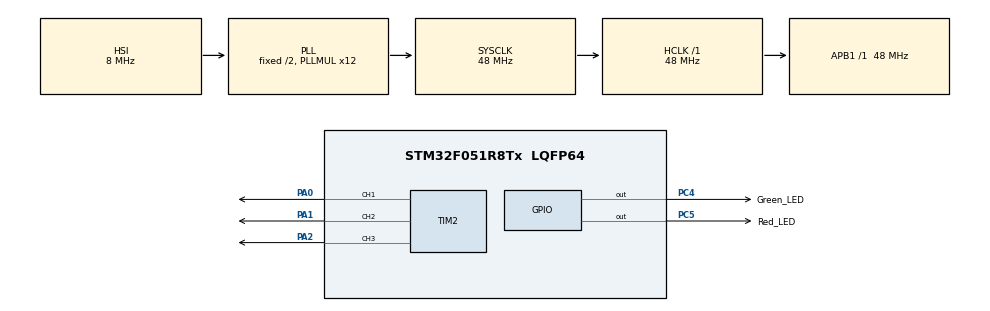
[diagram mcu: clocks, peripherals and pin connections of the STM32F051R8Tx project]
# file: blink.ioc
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Mcu.Family=STM32F0
Mcu.Name=STM32F051R8Tx
Mcu.Package=LQFP64
PA0.Signal=S_TIM2_CH1_ETR
PA1.Signal=S_TIM2_CH2
PA2.Signal=S_TIM2_CH3
PC4.GPIO_Label=Green_LED
PC4.Signal=GPIO_Output
PC5.GPIO_Label=Red_LED
PC5.Signal=GPIO_Output
ProjectManager.HeapSize=0x200
ProjectManager.StackSize=0x400
ProjectManager.TargetToolchain=STM32CubeIDE
RCC.AHBFreq_Value=48000000
RCC.APB1Freq_Value=48000000
RCC.APB1TimFreq_Value=48000000
RCC.HCLKFreq_Value=48000000
RCC.PLLMUL=RCC_PLL_MUL12
RCC.SYSCLKFreq_VALUE=48000000
RCC.SYSCLKSource=RCC_SYSCLKSOURCE_PLLCLK
SH.S_TIM2_CH1_ETR.0=TIM2_CH1,PWM Generation1 CH1
SH.S_TIM2_CH2.0=TIM2_CH2,PWM Generation2 CH2
SH.S_TIM2_CH3.0=TIM2_CH3,PWM Generation3 CH3
TIM2.Channel-PWM\ Generation1\ CH1=TIM_CHANNEL_1
TIM2.Channel-PWM\ Generation2\ CH2=TIM_CHANNEL_2
TIM2.Channel-PWM\ Generation3\ CH3=TIM_CHANNEL_3
VP_TIM2_VS_ClockSourceINT.Mode=Internal
VP_TIM3_VS_ClockSourceINT.Mode=Internal
board=STM32F0DISCOVERY

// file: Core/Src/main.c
/* USER CODE BEGIN Header */
/**
  ******************************************************************************
  * @file           : main.c
  * @brief          : Main program body
  ******************************************************************************
  * @attention
  *
  * <h2><center>&copy; Copyright (c) 2020 STMicroelectronics.
  * All rights reserved.</center></h2>
  *
  * This software component is licensed by ST under BSD 3-Clause license,
  * the "License"; You may not use this file except in compliance with the
  * License. You may obtain a copy of the License at:
  *                        opensource.org/licenses/BSD-3-Clause
  *
  ******************************************************************************
  */
/* USER CODE END Header */
#include "main.h"

TIM_HandleTypeDef htim2;
TIM_HandleTypeDef htim3;

void SystemClock_Config(void);
static void MX_GPIO_Init(void);
static void MX_TIM2_Init(void);
static void MX_TIM3_Init(void);

int main(void)
{

  /* MCU Configuration--------------------------------------------------------*/

  /* Reset of all peripherals, Initializes the Flash interface and the Systick. */
  HAL_Init();

  /* Configure the system clock */
  SystemClock_Config();

  /* Initialize all configured peripherals */
  MX_GPIO_Init();
  MX_TIM2_Init();
  MX_TIM3_Init();
  /* USER CODE BEGIN 2 */
  HAL_GPIO_WritePin(GPIOC, Green_LED_Pin, 1);  // enables the green light as a status light
  /* USER CODE END 2 */

  /* Infinite loop */
  while (1)
  {

  }
}

void SystemClock_Config(void)
{
  RCC_OscInitTypeDef RCC_OscInitStruct = {0};
  RCC_ClkInitTypeDef RCC_ClkInitStruct = {0};

  /** Initializes the RCC Oscillators according to the specified parameters
  * in the RCC_OscInitTypeDef structure.
  */
  RCC_OscInitStruct.OscillatorType = RCC_OSCILLATORTYPE_HSI;
  RCC_OscInitStruct.HSIState = RCC_HSI_ON;
  RCC_OscInitStruct.HSICalibrationValue = RCC_HSICALIBRATION_DEFAULT;
  RCC_OscInitStruct.PLL.PLLState = RCC_PLL_ON;
  RCC_OscInitStruct.PLL.PLLSource = RCC_PLLSOURCE_HSI;
  RCC_OscInitStruct.PLL.PLLMUL = RCC_PLL_MUL12;
  RCC_OscInitStruct.PLL.PREDIV = RCC_PREDIV_DIV1;
  if (HAL_RCC_OscConfig(&RCC_OscInitStruct) != HAL_OK)
  {
    Error_Handler();
  }
  /** Initializes the CPU, AHB and APB buses clocks
  */
  RCC_ClkInitStruct.ClockType = RCC_CLOCKTYPE_HCLK|RCC_CLOCKTYPE_SYSCLK
                              |RCC_CLOCKTYPE_PCLK1;
  RCC_ClkInitStruct.SYSCLKSource = RCC_SYSCLKSOURCE_PLLCLK;
  RCC_ClkInitStruct.AHBCLKDivider = RCC_SYSCLK_DIV1;
  RCC_ClkInitStruct.APB1CLKDivider = RCC_HCLK_DIV1;

  if (HAL_RCC_ClockConfig(&RCC_ClkInitStruct, FLASH_LATENCY_1) != HAL_OK)
  {
    Error_Handler();
  }
}

static void MX_TIM2_Init(void)
{

  TIM_ClockConfigTypeDef sClockSourceConfig = {0};
  TIM_MasterConfigTypeDef sMasterConfig = {0};
  TIM_OC_InitTypeDef sConfigOC = {0};

  htim2.Instance = TIM2;
  htim2.Init.Prescaler = 0;
  htim2.Init.CounterMode = TIM_COUNTERMODE_UP;
  htim2.Init.Period = 4294967295;
  htim2.Init.ClockDivision = TIM_CLOCKDIVISION_DIV1;
  htim2.Init.AutoReloadPreload = TIM_AUTORELOAD_PRELOAD_DISABLE;
  if (HAL_TIM_Base_Init(&htim2) != HAL_OK)
  {
    Error_Handler();
  }
  sClockSourceConfig.ClockSource = TIM_CLOCKSOURCE_INTERNAL;
  if (HAL_TIM_ConfigClockSource(&htim2, &sClockSourceConfig) != HAL_OK)
  {
    Error_Handler();
  }
  if (HAL_TIM_PWM_Init(&htim2) != HAL_OK)
  {
    Error_Handler();
  }
  sMasterConfig.MasterOutputTrigger = TIM_TRGO_RESET;
  sMasterConfig.MasterSlaveMode = TIM_MASTERSLAVEMODE_DISABLE;
  if (HAL_TIMEx_MasterConfigSynchronization(&htim2, &sMasterConfig) != HAL_OK)
  {
    Error_Handler();
  }
  sConfigOC.OCMode = TIM_OCMODE_PWM1;
  sConfigOC.Pulse = 0;
  sConfigOC.OCPolarity = TIM_OCPOLARITY_HIGH;
  sConfigOC.OCFastMode = TIM_OCFAST_DISABLE;
  if (HAL_TIM_PWM_ConfigChannel(&htim2, &sConfigOC, TIM_CHANNEL_1) != HAL_OK)
  {
    Error_Handler();
  }
  if (HAL_TIM_PWM_ConfigChannel(&htim2, &sConfigOC, TIM_CHANNEL_2) != HAL_OK)
  {
    Error_Handler();
  }
  if (HAL_TIM_PWM_ConfigChannel(&htim2, &sConfigOC, TIM_CHANNEL_3) != HAL_OK)
  {
    Error_Handler();
  }
  HAL_TIM_MspPostInit(&htim2);

}

static void MX_TIM3_Init(void)
{

  TIM_ClockConfigTypeDef sClockSourceConfig = {0};
  TIM_MasterConfigTypeDef sMasterConfig = {0};

  htim3.Instance = TIM3;
  htim3.Init.Prescaler = 0;
  htim3.Init.CounterMode = TIM_COUNTERMODE_UP;
  htim3.Init.Period = 65535;
  htim3.Init.ClockDivision = TIM_CLOCKDIVISION_DIV1;
  htim3.Init.AutoReloadPreload = TIM_AUTORELOAD_PRELOAD_DISABLE;
  if (HAL_TIM_Base_Init(&htim3) != HAL_OK)
  {
    Error_Handler();
  }
  sClockSourceConfig.ClockSource = TIM_CLOCKSOURCE_INTERNAL;
  if (HAL_TIM_ConfigClockSource(&htim3, &sClockSourceConfig) != HAL_OK)
  {
    Error_Handler();
  }
  sMasterConfig.MasterOutputTrigger = TIM_TRGO_RESET;
  sMasterConfig.MasterSlaveMode = TIM_MASTERSLAVEMODE_DISABLE;
  if (HAL_TIMEx_MasterConfigSynchronization(&htim3, &sMasterConfig) != HAL_OK)
  {
    Error_Handler();
  }

}

static void MX_GPIO_Init(void)
{
  GPIO_InitTypeDef GPIO_InitStruct = {0};

  /* GPIO Ports Clock Enable */
  __HAL_RCC_GPIOA_CLK_ENABLE();
  __HAL_RCC_GPIOC_CLK_ENABLE();

  /*Configure GPIO pin Output Level */
  HAL_GPIO_WritePin(GPIOC, Green_LED_Pin|Red_LED_Pin, GPIO_PIN_RESET);

  /*Configure GPIO pins : Green_LED_Pin Red_LED_Pin */
  GPIO_InitStruct.Pin = Green_LED_Pin|Red_LED_Pin;
  GPIO_InitStruct.Mode = GPIO_MODE_OUTPUT_PP;
  GPIO_InitStruct.Pull = GPIO_NOPULL;
  GPIO_InitStruct.Speed = GPIO_SPEED_FREQ_LOW;
  HAL_GPIO_Init(GPIOC, &GPIO_InitStruct);

}

void Error_Handler(void)
{
}

/************************ (C) COPYRIGHT STMicroelectronics *****END OF FILE****/
